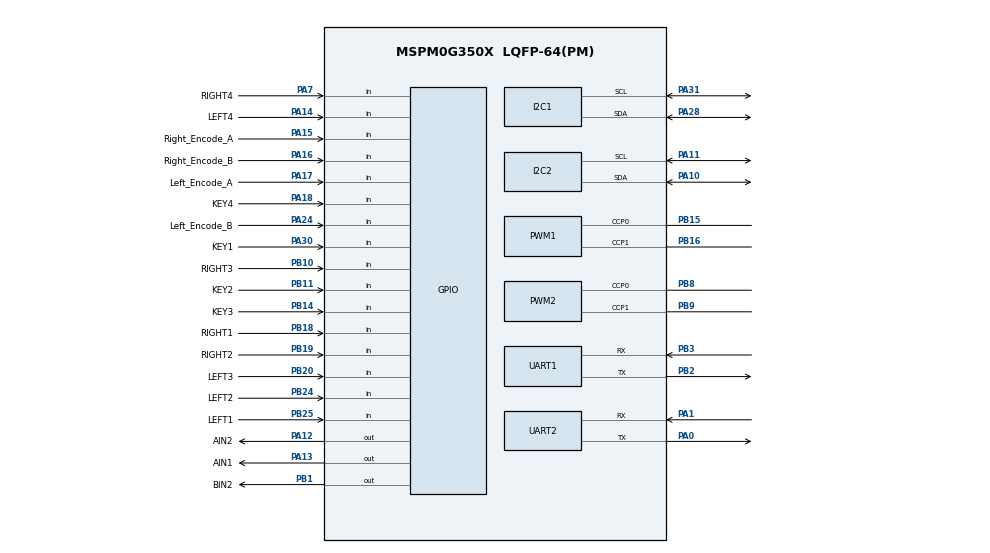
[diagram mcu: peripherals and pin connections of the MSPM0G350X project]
/**
 * @cliArgs --device "MSPM0G350X" --part "Default" --package "LQFP-64(PM)" --product "mspm0_sdk@2.10.00.04"
 * @versions {"tool":"1.26.2+4477"}
 */

/**
 * Import the modules used in this configuration.
 */
const GPIO   = scripting.addModule("/ti/driverlib/GPIO", {}, false);
const GPIO1  = GPIO.addInstance();
const GPIO2  = GPIO.addInstance();
const GPIO3  = GPIO.addInstance();
const GPIO4  = GPIO.addInstance();
const I2C    = scripting.addModule("/ti/driverlib/I2C", {}, false);
const I2C1   = I2C.addInstance();
const I2C2   = I2C.addInstance();
const PWM    = scripting.addModule("/ti/driverlib/PWM", {}, false);
const PWM1   = PWM.addInstance();
const PWM2   = PWM.addInstance();
const SYSCTL = scripting.addModule("/ti/driverlib/SYSCTL");
const TIMER  = scripting.addModule("/ti/driverlib/TIMER", {}, false);
const TIMER1 = TIMER.addInstance();
const UART   = scripting.addModule("/ti/driverlib/UART", {}, false);
const UART1  = UART.addInstance();
const UART2  = UART.addInstance();

/**
 * Write custom configuration values to the imported modules.
 */
const divider9       = system.clockTree["UDIV"];
divider9.divideValue = 2;

const mux4       = system.clockTree["EXHFMUX"];
mux4.inputSelect = "EXHFMUX_XTAL";

const mux8       = system.clockTree["HSCLKMUX"];
mux8.inputSelect = "HSCLKMUX_SYSPLL2X";

const mux12       = system.clockTree["SYSPLLMUX"];
mux12.inputSelect = "zSYSPLLMUX_HFCLK";

const pinFunction4        = system.clockTree["HFXT"];
pinFunction4.inputFreq    = 40;
pinFunction4.enable       = true;
pinFunction4.HFCLKMonitor = true;
pinFunction4.HFXTStartup  = 20;

GPIO1.$name                          = "TB6612";
GPIO1.associatedPins.create(4);
GPIO1.associatedPins[0].$name        = "AIN1";
GPIO1.associatedPins[0].assignedPort = "PORTA";
GPIO1.associatedPins[0].assignedPin  = "13";
GPIO1.associatedPins[0].pin.$assign  = "PA13";
GPIO1.associatedPins[1].$name        = "AIN2";
GPIO1.associatedPins[1].assignedPort = "PORTA";
GPIO1.associatedPins[1].assignedPin  = "12";
GPIO1.associatedPins[1].pin.$assign  = "PA12";
GPIO1.associatedPins[2].$name        = "BIN1";
GPIO1.associatedPins[2].assignedPort = "PORTB";
GPIO1.associatedPins[2].assignedPin  = "00";
GPIO1.associatedPins[3].$name        = "BIN2";
GPIO1.associatedPins[3].assignedPort = "PORTB";
GPIO1.associatedPins[3].assignedPin  = "01";
GPIO1.associatedPins[3].pin.$assign  = "PB1";

const Board = scripting.addModule("/ti/driverlib/Board", {}, false);

GPIO2.$name                              = "LINE";
GPIO2.associatedPins.create(8);
GPIO2.associatedPins[0].$name            = "LEFT1";
GPIO2.associatedPins[0].direction        = "INPUT";
GPIO2.associatedPins[0].internalResistor = "PULL_UP";
GPIO2.associatedPins[0].assignedPort     = "PORTB";
GPIO2.associatedPins[0].pin.$assign      = "PB25";
GPIO2.associatedPins[1].$name            = "LEFT2";
GPIO2.associatedPins[1].direction        = "INPUT";
GPIO2.associatedPins[1].assignedPort     = "PORTB";
GPIO2.associatedPins[1].internalResistor = "PULL_UP";
GPIO2.associatedPins[1].pin.$assign      = "PB24";
GPIO2.associatedPins[2].$name            = "LEFT3";
GPIO2.associatedPins[2].direction        = "INPUT";
GPIO2.associatedPins[2].assignedPort     = "PORTB";
GPIO2.associatedPins[2].internalResistor = "PULL_UP";
GPIO2.associatedPins[2].pin.$assign      = "PB20";
GPIO2.associatedPins[3].direction        = "INPUT";
GPIO2.associatedPins[3].$name            = "LEFT4";
GPIO2.associatedPins[3].internalResistor = "PULL_UP";
GPIO2.associatedPins[3].assignedPort     = "PORTA";
GPIO2.associatedPins[3].pin.$assign      = "PA14";
GPIO2.associatedPins[4].$name            = "RIGHT1";
GPIO2.associatedPins[4].direction        = "INPUT";
GPIO2.associatedPins[4].internalResistor = "PULL_UP";
GPIO2.associatedPins[4].assignedPort     = "PORTB";
GPIO2.associatedPins[4].pin.$assign      = "PB18";
GPIO2.associatedPins[5].$name            = "RIGHT2";
GPIO2.associatedPins[5].direction        = "INPUT";
GPIO2.associatedPins[5].internalResistor = "PULL_UP";
GPIO2.associatedPins[5].assignedPort     = "PORTB";
GPIO2.associatedPins[5].pin.$assign      = "PB19";
GPIO2.associatedPins[6].$name            = "RIGHT3";
GPIO2.associatedPins[6].direction        = "INPUT";
GPIO2.associatedPins[6].internalResistor = "PULL_UP";
GPIO2.associatedPins[6].assignedPort     = "PORTB";
GPIO2.associatedPins[6].pin.$assign      = "PB10";
GPIO2.associatedPins[7].$name            = "RIGHT4";
GPIO2.associatedPins[7].direction        = "INPUT";
GPIO2.associatedPins[7].internalResistor = "PULL_UP";
GPIO2.associatedPins[7].pin.$assign      = "PA7";

GPIO3.$name                              = "KEY";
GPIO3.associatedPins.create(4);
GPIO3.associatedPins[0].$name            = "KEY1";
GPIO3.associatedPins[0].direction        = "INPUT";
GPIO3.associatedPins[0].internalResistor = "PULL_UP";
GPIO3.associatedPins[0].pin.$assign      = "PA30";
GPIO3.associatedPins[1].$name            = "KEY2";
GPIO3.associatedPins[1].direction        = "INPUT";
GPIO3.associatedPins[1].internalResistor = "PULL_UP";
GPIO3.associatedPins[1].pin.$assign      = "PB11";
GPIO3.associatedPins[2].$name            = "KEY3";
GPIO3.associatedPins[2].direction        = "INPUT";
GPIO3.associatedPins[2].internalResistor = "PULL_UP";
GPIO3.associatedPins[2].pin.$assign      = "PB14";
GPIO3.associatedPins[3].$name            = "KEY4";
GPIO3.associatedPins[3].direction        = "INPUT";
GPIO3.associatedPins[3].internalResistor = "PULL_UP";
GPIO3.associatedPins[3].pin.$assign      = "PA18";

GPIO4.$name                               = "Encoder";
GPIO4.associatedPins.create(4);
GPIO4.associatedPins[0].$name             = "Left_Encode_A";
GPIO4.associatedPins[0].direction         = "INPUT";
GPIO4.associatedPins[0].internalResistor  = "PULL_UP";
GPIO4.associatedPins[0].interruptEn       = true;
GPIO4.associatedPins[0].interruptPriority = "0";
GPIO4.associatedPins[0].polarity          = "RISE_FALL";
GPIO4.associatedPins[0].pin.$assign       = "PA17";
GPIO4.associatedPins[1].$name             = "Left_Encode_B";
GPIO4.associatedPins[1].direction         = "INPUT";
GPIO4.associatedPins[1].internalResistor  = "PULL_UP";
GPIO4.associatedPins[1].pin.$assign       = "PA24";
GPIO4.associatedPins[2].$name             = "Right_Encode_A";
GPIO4.associatedPins[2].direction         = "INPUT";
GPIO4.associatedPins[2].internalResistor  = "PULL_UP";
GPIO4.associatedPins[2].interruptEn       = true;
GPIO4.associatedPins[2].interruptPriority = "0";
GPIO4.associatedPins[2].polarity          = "RISE_FALL";
GPIO4.associatedPins[2].pin.$assign       = "PA15";
GPIO4.associatedPins[3].$name             = "Right_Encode_B";
GPIO4.associatedPins[3].direction         = "INPUT";
GPIO4.associatedPins[3].internalResistor  = "PULL_UP";
GPIO4.associatedPins[3].pin.$assign       = "PA16";

I2C1.$name                             = "OLED";
I2C1.basicEnableController             = true;
I2C1.advControllerRXFIFOTRIG           = "BYTES_8";
I2C1.advControllerTXFIFOTRIG           = "BYTES_7";
I2C1.enableDMAEvent1                   = false;
I2C1.enableDMAEvent2                   = false;
I2C1.peripheral.sdaPin.$assign         = "PA28";
I2C1.peripheral.sclPin.$assign         = "PA31";
I2C1.sdaPinConfig.hideOutputInversion  = scripting.forceWrite(false);
I2C1.sdaPinConfig.onlyInternalResistor = scripting.forceWrite(false);
I2C1.sdaPinConfig.passedPeripheralType = scripting.forceWrite("Digital");
I2C1.sdaPinConfig.$name                = "ti_driverlib_gpio_GPIOPinGeneric4";
I2C1.sclPinConfig.hideOutputInversion  = scripting.forceWrite(false);
I2C1.sclPinConfig.onlyInternalResistor = scripting.forceWrite(false);
I2C1.sclPinConfig.passedPeripheralType = scripting.forceWrite("Digital");
I2C1.sclPinConfig.$name                = "ti_driverlib_gpio_GPIOPinGeneric5";

I2C2.$name                             = "MPU6050";
I2C2.basicEnableController             = true;
I2C2.advControllerTXFIFOTRIG           = "BYTES_7";
I2C2.advControllerRXFIFOTRIG           = "BYTES_8";
I2C2.peripheral.sdaPin.$assign         = "PA10";
I2C2.peripheral.sclPin.$assign         = "PA11";
I2C2.sdaPinConfig.hideOutputInversion  = scripting.forceWrite(false);
I2C2.sdaPinConfig.onlyInternalResistor = scripting.forceWrite(false);
I2C2.sdaPinConfig.passedPeripheralType = scripting.forceWrite("Digital");
I2C2.sdaPinConfig.$name                = "ti_driverlib_gpio_GPIOPinGeneric0";
I2C2.sclPinConfig.hideOutputInversion  = scripting.forceWrite(false);
I2C2.sclPinConfig.onlyInternalResistor = scripting.forceWrite(false);
I2C2.sclPinConfig.passedPeripheralType = scripting.forceWrite("Digital");
I2C2.sclPinConfig.$name                = "ti_driverlib_gpio_GPIOPinGeneric1";

PWM1.$name                      = "PWM_0";
PWM1.timerStartTimer            = true;
PWM1.clockDivider               = 8;
PWM1.peripheral.$assign         = "TIMG7";
PWM1.peripheral.ccp0Pin.$assign = "PB15";
PWM1.peripheral.ccp1Pin.$assign = "PB16";
PWM1.PWM_CHANNEL_0.$name        = "ti_driverlib_pwm_PWMTimerCC0";
PWM1.PWM_CHANNEL_0.invert       = true;
PWM1.PWM_CHANNEL_1.$name        = "ti_driverlib_pwm_PWMTimerCC1";
PWM1.PWM_CHANNEL_1.invert       = true;
PWM1.ccp0PinConfig.$name        = "ti_driverlib_gpio_GPIOPinGeneric2";
PWM1.ccp1PinConfig.$name        = "ti_driverlib_gpio_GPIOPinGeneric3";

PWM2.$name                              = "PWM_Servo";
PWM2.clockDivider                       = 8;
PWM2.clockPrescale                      = 8;
PWM2.timerCount                         = 25000;
PWM2.timerStartTimer                    = true;
PWM2.peripheral.ccp0Pin.$assign         = "PB8";
PWM2.peripheral.ccp1Pin.$assign         = "PB9";
PWM2.PWM_CHANNEL_0.$name                = "ti_driverlib_pwm_PWMTimerCC2";
PWM2.PWM_CHANNEL_1.$name                = "ti_driverlib_pwm_PWMTimerCC3";
PWM2.ccp0PinConfig.direction            = scripting.forceWrite("OUTPUT");
PWM2.ccp0PinConfig.hideOutputInversion  = scripting.forceWrite(false);
PWM2.ccp0PinConfig.onlyInternalResistor = scripting.forceWrite(false);
PWM2.ccp0PinConfig.passedPeripheralType = scripting.forceWrite("Digital");
PWM2.ccp0PinConfig.$name                = "ti_driverlib_gpio_GPIOPinGeneric8";
PWM2.ccp1PinConfig.direction            = scripting.forceWrite("OUTPUT");
PWM2.ccp1PinConfig.hideOutputInversion  = scripting.forceWrite(false);
PWM2.ccp1PinConfig.onlyInternalResistor = scripting.forceWrite(false);
PWM2.ccp1PinConfig.passedPeripheralType = scripting.forceWrite("Digital");
PWM2.ccp1PinConfig.$name                = "ti_driverlib_gpio_GPIOPinGeneric9";

SYSCTL.forceDefaultClkConfig = true;
SYSCTL.clockTreeEn           = true;
SYSCTL.validateClkStatus     = true;

TIMER1.$name              = "PID_TIMER";
TIMER1.timerClkDiv        = 8;
TIMER1.interrupts         = ["ZERO"];
TIMER1.timerMode          = "PERIODIC";
TIMER1.timerPeriod        = "5000 us";
TIMER1.peripheral.$assign = "TIMG0";

UART1.$name                            = "UART_Cam";
UART1.targetBaudRate                   = 115200;
UART1.peripheral.rxPin.$assign         = "PB3";
UART1.peripheral.txPin.$assign         = "PB2";
UART1.txPinConfig.direction            = scripting.forceWrite("OUTPUT");
UART1.txPinConfig.hideOutputInversion  = scripting.forceWrite(false);
UART1.txPinConfig.onlyInternalResistor = scripting.forceWrite(false);
UART1.txPinConfig.passedPeripheralType = scripting.forceWrite("Digital");
UART1.txPinConfig.$name                = "ti_driverlib_gpio_GPIOPinGeneric6";
UART1.rxPinConfig.hideOutputInversion  = scripting.forceWrite(false);
UART1.rxPinConfig.onlyInternalResistor = scripting.forceWrite(false);
UART1.rxPinConfig.passedPeripheralType = scripting.forceWrite("Digital");
UART1.rxPinConfig.$name                = "ti_driverlib_gpio_GPIOPinGeneric7";

UART2.$name                    = "UART_0";
UART2.targetBaudRate           = 115200;
UART2.peripheral.$assign       = "UART0";
UART2.peripheral.rxPin.$assign = "PA1";
UART2.peripheral.txPin.$assign = "PA0";
UART2.txPinConfig.$name        = "ti_driverlib_gpio_GPIOPinGeneric10";
UART2.rxPinConfig.$name        = "ti_driverlib_gpio_GPIOPinGeneric11";

/**
 * Pinmux solution for unlocked pins/peripherals. This ensures that minor changes to the automatic solver in a future
 * version of the tool will not impact the pinmux you originally saw.  These lines can be completely deleted in order to
 * re-solve from scratch.
 */
pinFunction4.peripheral.$suggestSolution           = "SYSCTL";
pinFunction4.peripheral.hfxInPin.$suggestSolution  = "PA5";
pinFunction4.peripheral.hfxOutPin.$suggestSolution = "PA6";
GPIO1.associatedPins[2].pin.$suggestSolution       = "PB0";
Board.peripheral.$suggestSolution                  = "DEBUGSS";
Board.peripheral.swclkPin.$suggestSolution         = "PA20";
Board.peripheral.swdioPin.$suggestSolution         = "PA19";
I2C1.peripheral.$suggestSolution                   = "I2C0";
I2C2.peripheral.$suggestSolution                   = "I2C1";
PWM2.peripheral.$suggestSolution                   = "TIMA0";
UART1.peripheral.$suggestSolution                  = "UART3";
